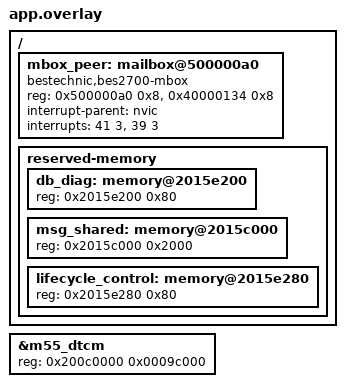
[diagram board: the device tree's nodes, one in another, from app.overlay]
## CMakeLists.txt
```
# SPDX-License-Identifier: Apache-2.0
cmake_minimum_required(VERSION 3.20.0)
find_package(Zephyr REQUIRED HINTS $ENV{ZEPHYR_BASE})
project(bes2700_m55_dual_message)
target_sources(app PRIVATE src/main.c)
if(CONFIG_BES2700_M55_RESTART)
  target_sources(app PRIVATE ${CMAKE_CURRENT_LIST_DIR}/../../../platforms/bes2700yp/lifecycle/peer.c)
endif()
target_sources(app PRIVATE src/reset_trace.S)

target_sources(app PRIVATE ${CMAKE_CURRENT_LIST_DIR}/../../../platforms/bes2700yp/ipc/worker.c)
target_include_directories(app PRIVATE ${CMAKE_CURRENT_LIST_DIR}/../../../platforms/bes2700yp/ipc)

get_filename_component(bes_workspace ${CMAKE_CURRENT_LIST_DIR}/../../../.. ABSOLUTE)
get_filename_component(bes_build ${PROJECT_BINARY_DIR}/.. ABSOLUTE)
zephyr_compile_options(-ffile-prefix-map=${bes_workspace}=workspace
  -ffile-prefix-map=${bes_build}=build
  $<$<COMPILE_LANGUAGE:ASM>:-Wa,--debug-prefix-map=${bes_workspace}=workspace>
  $<$<COMPILE_LANGUAGE:ASM>:-Wa,--debug-prefix-map=${bes_build}=build>)
```

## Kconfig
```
# SPDX-License-Identifier: Apache-2.0

mainmenu "BES2700YP dual-core validation"
source "Kconfig.zephyr"
config DUAL_CC_PAIR
 hex "Message image pair identity"
 default 0
config DUAL_M55_BUILD
 hex "M55 image source identity"
 default 0

config BES2700_DUAL_DIAGNOSTICS
 bool
 default y
 select SOC_EARLY_RESET_HOOK

config DUAL_IPC_SECONDS
 int "Active concurrent traffic duration"
 range 600 3600
 default 3600

config DUAL_MSG_MODE
 int "Message validation: 1=sequential, 2=concurrent, 3=negative"
 range 1 3
 default 1

config BES2700_M55_RESTART
 bool "Validate RAM-retained M55 CPU restart"
 default n

config BES2700_M55_FAULT_CASE
 int "M55 fault injection: 0=off, 1=READY, 2=heartbeat, 3=IPC, 4=QUIESCE, 5=fatal, 6=lost fatal"
 range 0 6
 default 0
 help
   Validation only. Nonzero values require the retained-RAM lifecycle.
   Select a controlled peer fault in the validation application only.

config BES2700_M55_RECOVERY
 bool "Validate one M55 recovery after isolation"
 depends on BES2700_M55_RESTART && BES2700_M55_FAULT_CASE > 0
 default n
 help
   Rebuild the BTH worker and reload M55 once with a new session.
   Inject only in session 1; failed recovery remains isolated.

config BES2700_M55_RECOVERY_FAIL_STEP
 int "Recovery failure injection: 0=off, 1=REPARK, 3=load, 5=new READY"
 range 0 5
 default 0
 help
   Validation only. Values 1 and 3 inject an operation failure before
   touching hardware or loading RAM. Value 5 stops the replacement
   M55 before READY. Profiles reject other nonzero values.
```

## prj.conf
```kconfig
CONFIG_BOOT_BANNER=n
CONFIG_LOG=n
CONFIG_PRINTK=n
CONFIG_CONSOLE=n
CONFIG_ASSERT=y
CONFIG_INIT_STACKS=y
CONFIG_THREAD_STACK_INFO=y
CONFIG_STACK_SENTINEL=y
CONFIG_TICKLESS_KERNEL=n
CONFIG_SYS_CLOCK_TICKS_PER_SEC=1000
CONFIG_MAIN_STACK_SIZE=3072
CONFIG_ISR_STACK_SIZE=2048
CONFIG_PM=n
CONFIG_ARM_MPU=n
CONFIG_HW_STACK_PROTECTION=n
CONFIG_FPU=n

CONFIG_MBOX=y
CONFIG_MBOX_BES2700=y
```

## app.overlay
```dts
/* Reserve future 8 KiB IPC queues even in V08a. */
&m55_dtcm { reg = <0x200c0000 0x0009c000>; };

/* Copyright The Zephyr Project Contributors */
/* SPDX-License-Identifier: Apache-2.0 */

/ {
	mbox_peer: mailbox@500000a0 {
		compatible = "bestechnic,bes2700-mbox";
		reg = <0x500000a0 0x8>, <0x40000134 0x8>;
		reg-names = "sys", "bth";
		interrupt-parent = <&nvic>;
		interrupts = <41 3>, <39 3>;
		interrupt-names = "rx", "tx-done";
		#mbox-cells = <1>;
		status = "okay";
	};
};

/ { reserved-memory { db_diag: memory@2015e200 { reg = <0x2015e200 0x80>; }; }; };
/ { reserved-memory { msg_shared: memory@2015c000 { reg = <0x2015c000 0x2000>; }; }; };

/* Last shared writer publishes quiescence before CPU reset. */
/ { reserved-memory { lifecycle_control: memory@2015e280 { reg = <0x2015e280 0x80>; }; }; };
```

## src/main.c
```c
/* SPDX-License-Identifier: Apache-2.0 */
#include <zephyr/kernel.h>
#include <cmsis_core.h>
#include <bes2700_dual_boot.h>
#include <bes2700_dual_trace.h>
#ifdef CONFIG_BES2700_M55_RESTART
#include <bes2700_lifecycle.h>
#include <bes2700_peer_health.h>
#endif
__attribute__((section(".bes2700_m55_shared"))) volatile struct dual_status dual_shared;
static volatile uint32_t initialized_probe = 0x5aa55aa5;
static volatile uint32_t zero_probe;
/* Keep the epoch fixed: relative sleeps accumulate work and tick rounding. */
#define HEARTBEAT_PERIOD_MS 100
#define HEARTBEAT_MAX_LATE_MS 20
static void publish(uint32_t stage, uint32_t error, size_t stack, uint32_t ms)
{
 dual_shared.seq++; __DMB();
 dual_shared.stage = stage; dual_shared.error = error;
 if (!error) { dual_shared.beat++; }
 dual_shared.ms = ms;
 dual_shared.cycles = k_cycle_get_32(); dual_shared.hz = CONFIG_SYS_CLOCK_HW_CYCLES_PER_SEC;
 dual_shared.cpuid = SCB->CPUID; dual_shared.vtor = SCB->VTOR;
 dual_shared.control = __get_CONTROL(); dual_shared.primask = __get_PRIMASK();
 dual_shared.basepri = __get_BASEPRI(); dual_shared.mpu = MPU->CTRL; dual_shared.ccr = SCB->CCR;
 dual_shared.stack = stack; dual_shared.guard = DUAL_GUARD;
 __DMB(); dual_shared.seq++; __DMB();
}
void k_sys_fatal_error_handler(unsigned int reason, const struct arch_esf *esf)
{
#if CONFIG_BES2700_M55_FAULT_CASE == 6
 /* Exercise loss of a fatal publication, including a writer left odd. */
 if (BES_LIFECYCLE_CTL->session==1) {
  dual_shared.seq |= 1U;__DSB();__disable_irq();for (;;) { __NOP(); }
 }
#endif
 if (esf) {
  DUAL_TRACE->pc=esf->basic.pc; DUAL_TRACE->lr=esf->basic.lr;
  DUAL_TRACE->xpsr=esf->basic.xpsr; DUAL_TRACE->esf_valid=1;
 }
 dual_trace_record(255, reason);
 dual_shared.seq |= 1U;
 dual_shared.stage = 255; dual_shared.error = 100 + reason;
 dual_shared.guard = DUAL_GUARD;
 __DMB(); dual_shared.seq++; __DSB();
 __disable_irq(); for (;;) { __NOP(); }
}
#if CONFIG_BES2700_M55_FAULT_CASE > 0
#if !defined(CONFIG_BES2700_M55_RESTART)
#error "M55 fault injection requires lifecycle support"
#endif
#if CONFIG_BES2700_M55_FAULT_CASE == 3 || CONFIG_BES2700_M55_FAULT_CASE == 4
static bool first_session(void)
{
 return BES_LIFECYCLE_CTL->magic==BES_LIFECYCLE_MAGIC &&
  BES_LIFECYCLE_CTL->layout==BES_LIFECYCLE_LAYOUT &&
  BES_LIFECYCLE_CTL->guard==BES_LIFECYCLE_GUARD && BES_LIFECYCLE_CTL->session==1;
}
#endif
#if CONFIG_BES2700_M55_FAULT_CASE != 3 && CONFIG_BES2700_M55_FAULT_CASE != 4
static void inject_fault(void)
{
#ifdef CONFIG_BES2700_M55_RECOVERY
 /* Test selection is separate from health policy. Validate the control block
  * before suppressing injection in the one permitted replacement session. */
 if (BES_LIFECYCLE_CTL->magic==BES_LIFECYCLE_MAGIC &&
     BES_LIFECYCLE_CTL->layout==BES_LIFECYCLE_LAYOUT &&
     BES_LIFECYCLE_CTL->guard==BES_LIFECYCLE_GUARD &&
     BES_LIFECYCLE_CTL->session==2) { return; }
#endif
#if CONFIG_BES2700_M55_FAULT_CASE == 5 || CONFIG_BES2700_M55_FAULT_CASE == 6
 BES_LIFECYCLE_CTL->unused[0]=CONFIG_BES2700_M55_FAULT_CASE;__DSB();
 k_panic();
#endif
 __disable_irq();
 dual_trace_record(BES_PEER_INJECTION_STAGE,CONFIG_BES2700_M55_FAULT_CASE);
 for (;;) { __NOP(); }
}
#endif
#endif
int main(void)
{
 dual_trace_record(4, 0);
 dual_shared.magic = 0; dual_shared.seq = 0; dual_shared.beat = 0;
 dual_shared.layout = DUAL_LAYOUT; dual_shared.build = CONFIG_DUAL_M55_BUILD;
 __DMB(); dual_shared.magic = DUAL_MAGIC;
#if CONFIG_BES2700_M55_FAULT_CASE == 1
 inject_fault();
#endif
#if CONFIG_BES2700_M55_RECOVERY_FAIL_STEP == 5
 if(BES_LIFECYCLE_CTL->session==2) {
  __disable_irq();dual_trace_record(BES_PEER_INJECTION_STAGE,1);
  for(;;) { __NOP(); }
 }
#endif
 int64_t deadline = k_uptime_get();
 for (;;) {
#ifdef CONFIG_BES2700_M55_RESTART
  if (bes2700_lifecycle_peer_poll()) {
   publish(255,10,0,k_uptime_get_32());return 0;
  }
#endif
#if CONFIG_BES2700_M55_FAULT_CASE == 2 || CONFIG_BES2700_M55_FAULT_CASE == 5 || CONFIG_BES2700_M55_FAULT_CASE == 6
  if (dual_shared.beat >= BES_PEER_INJECTION_BEATS) { inject_fault(); }
#endif
  size_t free = 0;
  uint32_t error = initialized_probe != 0x5aa55aa5 || zero_probe ? 1 : 0;
  if (k_thread_stack_space_get(k_current_get(), &free) || free < 128) { error = 2; }
  if (MPU->CTRL || (SCB->CCR & ((1U << 16) | (1U << 17))) ||
      SCB->VTOR != DUAL_ITCM || __get_PRIMASK() || __get_BASEPRI() || __get_CONTROL() != 2) { error = 3; }
  int64_t now = k_uptime_get();
  /* Check after self-tests, immediately before publishing. Never catch up by
   * emitting several heartbeats after a stall. Existing failures keep priority. */
  if (!error && (now < deadline || now - deadline > HEARTBEAT_MAX_LATE_MS)) { error = 4; }
  publish(error ? 255 : 2, error, free, (uint32_t)now);
  uint32_t trace_stage=error?255:5,trace_reason=error;
#if CONFIG_BES2700_M55_FAULT_CASE == 3
  extern int q_fault_injected(void);
  if(!error && first_session() && q_fault_injected()) { trace_stage=BES_PEER_INJECTION_STAGE;trace_reason=3; }
#elif CONFIG_BES2700_M55_FAULT_CASE == 4
  if(!error && first_session() && BES_LIFECYCLE_CTL->quiesce==1) { trace_stage=BES_PEER_INJECTION_STAGE;trace_reason=4; }
#endif
  if(error || DUAL_TRACE->stage!=trace_stage) { dual_trace_record(trace_stage,trace_reason); }
  if (error) { return 0; }
  deadline += HEARTBEAT_PERIOD_MS;
  k_sleep(K_TIMEOUT_ABS_MS(deadline));
 }
}
```
